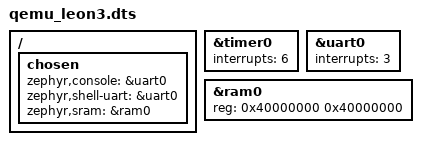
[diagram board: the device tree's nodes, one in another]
/*
 * Copyright (c) 2020 Cobham Gaisler AB
 *
 * SPDX-License-Identifier: Apache-2.0
 */

/dts-v1/;

#include <gaisler/leon3soc.dtsi>

/ {
	chosen {
		zephyr,console = &uart0;
		zephyr,shell-uart = &uart0;
		zephyr,sram = &ram0;
	};
};

&timer0 {
	interrupts = <6>;
};

&uart0 {
	interrupts = <3>;
	status = "okay";
};

&ram0 {
	reg = <0x40000000 0x40000000>;
};
